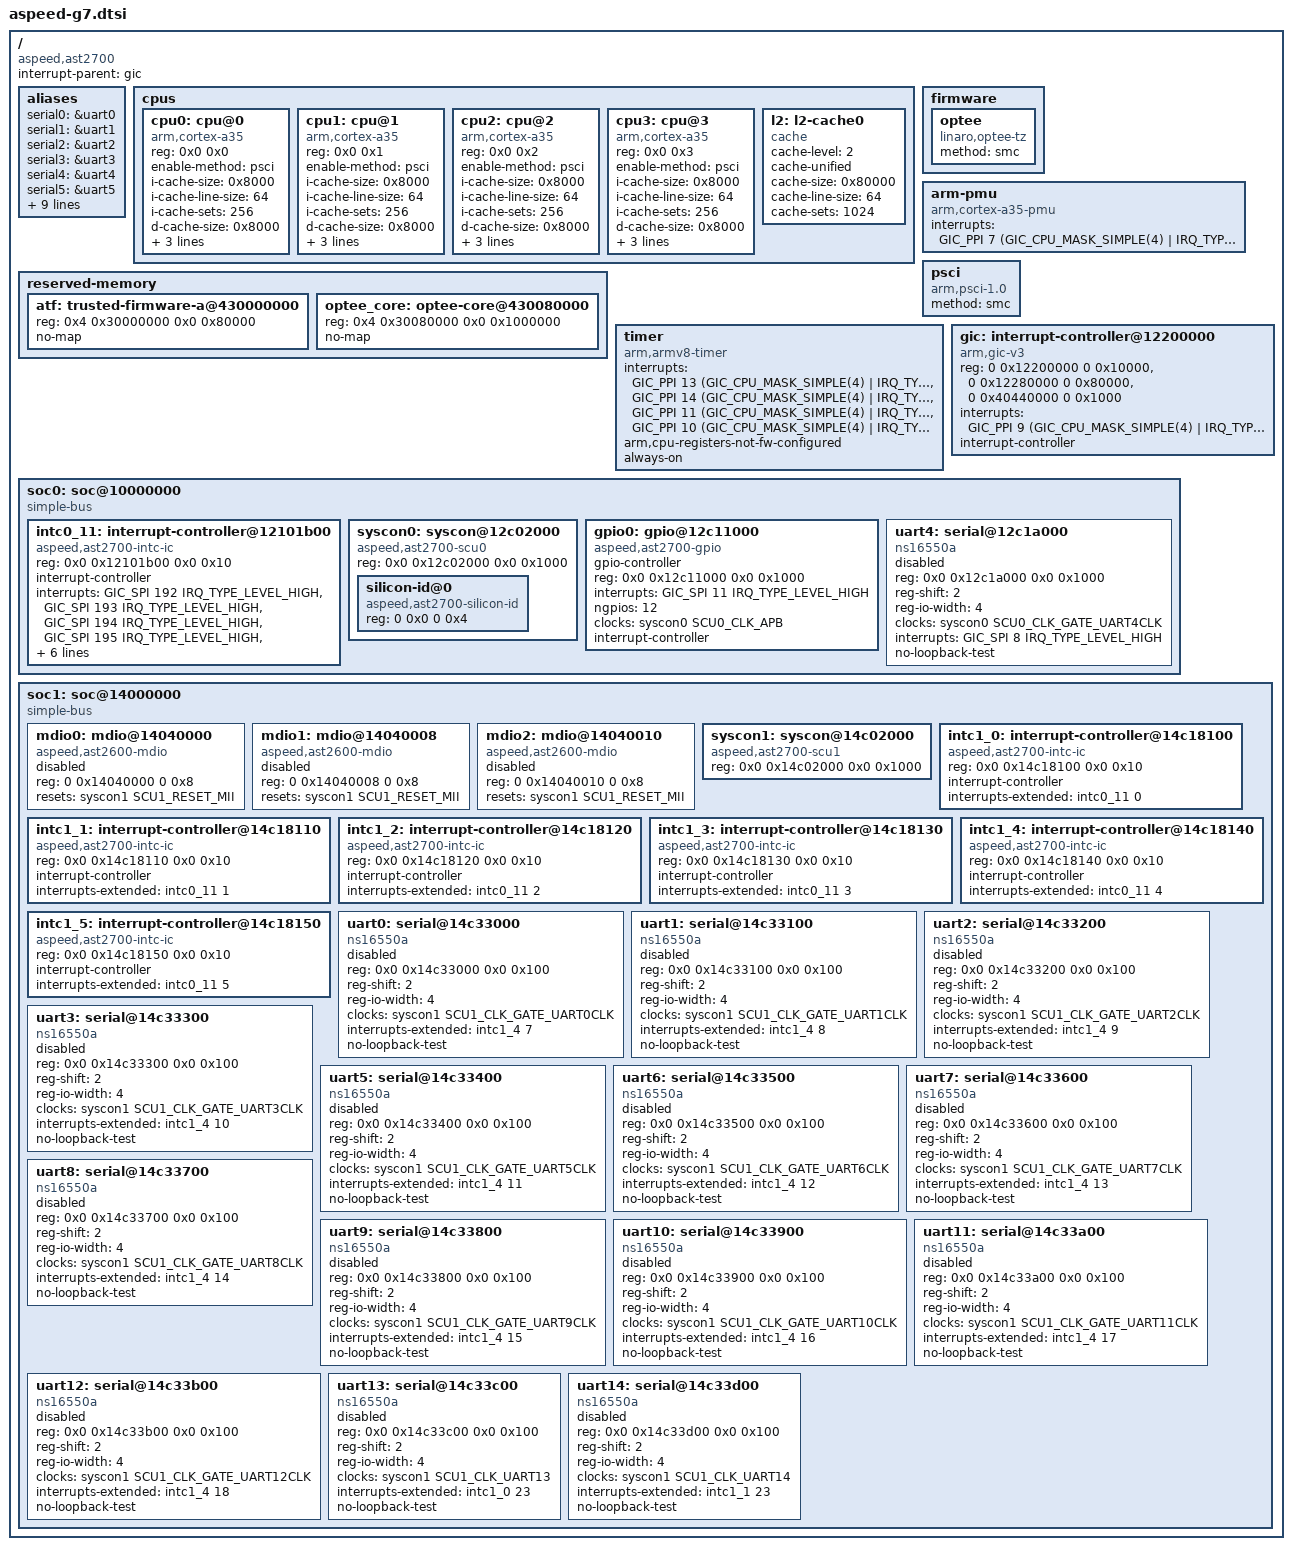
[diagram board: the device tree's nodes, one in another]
// SPDX-License-Identifier: GPL-2.0-or-later
#include <dt-bindings/clock/aspeed,ast2700-scu.h>
#include <dt-bindings/reset/aspeed,ast2700-scu.h>
#include <dt-bindings/interrupt-controller/arm-gic.h>

/ {
	compatible = "aspeed,ast2700";
	#address-cells = <2>;
	#size-cells = <2>;
	interrupt-parent = <&gic>;

	aliases {
		serial0 = &uart0;
		serial1 = &uart1;
		serial2 = &uart2;
		serial3 = &uart3;
		serial4 = &uart4;
		serial5 = &uart5;
		serial6 = &uart6;
		serial7 = &uart7;
		serial8 = &uart8;
		serial9 = &uart9;
		serial10 = &uart10;
		serial11 = &uart11;
		serial12 = &uart12;
		serial13 = &uart13;
		serial14 = &uart14;
	};

	cpus {
		#address-cells = <2>;
		#size-cells = <0>;

		cpu0: cpu@0 {
			device_type = "cpu";
			compatible = "arm,cortex-a35";
			reg = <0x0 0x0>;
			enable-method = "psci";
			i-cache-size = <0x8000>;
			i-cache-line-size = <64>;
			i-cache-sets = <256>;
			d-cache-size = <0x8000>;
			d-cache-line-size = <64>;
			d-cache-sets = <128>;
			next-level-cache = <&l2>;
		};

		cpu1: cpu@1 {
			device_type = "cpu";
			compatible = "arm,cortex-a35";
			reg = <0x0 0x1>;
			enable-method = "psci";
			i-cache-size = <0x8000>;
			i-cache-line-size = <64>;
			i-cache-sets = <256>;
			d-cache-size = <0x8000>;
			d-cache-line-size = <64>;
			d-cache-sets = <128>;
			next-level-cache = <&l2>;
		};

		cpu2: cpu@2 {
			device_type = "cpu";
			compatible = "arm,cortex-a35";
			reg = <0x0 0x2>;
			enable-method = "psci";
			i-cache-size = <0x8000>;
			i-cache-line-size = <64>;
			i-cache-sets = <256>;
			d-cache-size = <0x8000>;
			d-cache-line-size = <64>;
			d-cache-sets = <128>;
			next-level-cache = <&l2>;
		};

		cpu3: cpu@3 {
			device_type = "cpu";
			compatible = "arm,cortex-a35";
			reg = <0x0 0x3>;
			enable-method = "psci";
			i-cache-size = <0x8000>;
			i-cache-line-size = <64>;
			i-cache-sets = <256>;
			d-cache-size = <0x8000>;
			d-cache-line-size = <64>;
			d-cache-sets = <128>;
			next-level-cache = <&l2>;
		};

		l2: l2-cache0 {
			compatible = "cache";
			cache-level = <2>;
			cache-unified;
			cache-size = <0x80000>;
			cache-line-size = <64>;
			cache-sets = <1024>;
		};
	};

	firmware {
		optee: optee {
			compatible = "linaro,optee-tz";
			method = "smc";
		};
	};

	reserved-memory {
		#address-cells = <2>;
		#size-cells = <2>;
		ranges;

		atf: trusted-firmware-a@430000000 {
			reg = <0x4 0x30000000 0x0 0x80000>;
			no-map;
		};

		optee_core: optee-core@430080000 {
			reg = <0x4 0x30080000 0x0 0x1000000>;
			no-map;
		};
	};

	arm-pmu {
		compatible = "arm,cortex-a35-pmu";
		interrupts = <GIC_PPI 7 (GIC_CPU_MASK_SIMPLE(4) | IRQ_TYPE_LEVEL_HIGH)>;
	};

	psci {
		compatible = "arm,psci-1.0";
		method = "smc";
	};

	timer {
		compatible = "arm,armv8-timer";
		interrupts = <GIC_PPI 13 (GIC_CPU_MASK_SIMPLE(4) | IRQ_TYPE_LEVEL_LOW)>,
			     <GIC_PPI 14 (GIC_CPU_MASK_SIMPLE(4) | IRQ_TYPE_LEVEL_LOW)>,
			     <GIC_PPI 11 (GIC_CPU_MASK_SIMPLE(4) | IRQ_TYPE_LEVEL_LOW)>,
			     <GIC_PPI 10 (GIC_CPU_MASK_SIMPLE(4) | IRQ_TYPE_LEVEL_LOW)>;
		arm,cpu-registers-not-fw-configured;
		always-on;
	};

	gic: interrupt-controller@12200000 {
		compatible = "arm,gic-v3";
		reg = <0 0x12200000 0 0x10000>, /* GICD */
		      <0 0x12280000 0 0x80000>, /* GICR */
		      <0 0x40440000 0 0x1000>;  /* GICC */
		interrupts = <GIC_PPI 9 (GIC_CPU_MASK_SIMPLE(4) | IRQ_TYPE_LEVEL_HIGH)>;
		#interrupt-cells = <3>;
		interrupt-controller;
	};

	soc0: soc@10000000 {
		compatible = "simple-bus";
		#address-cells = <2>;
		#size-cells = <2>;
		ranges;

		intc0_11: interrupt-controller@12101b00 {
			compatible = "aspeed,ast2700-intc-ic";
			reg = <0x0 0x12101b00 0x0 0x10>;
			#interrupt-cells = <1>;
			interrupt-controller;
			interrupts = <GIC_SPI 192 IRQ_TYPE_LEVEL_HIGH>,
					<GIC_SPI 193 IRQ_TYPE_LEVEL_HIGH>,
					<GIC_SPI 194 IRQ_TYPE_LEVEL_HIGH>,
					<GIC_SPI 195 IRQ_TYPE_LEVEL_HIGH>,
					<GIC_SPI 196 IRQ_TYPE_LEVEL_HIGH>,
					<GIC_SPI 197 IRQ_TYPE_LEVEL_HIGH>,
					<GIC_SPI 198 IRQ_TYPE_LEVEL_HIGH>,
					<GIC_SPI 199 IRQ_TYPE_LEVEL_HIGH>,
					<GIC_SPI 200 IRQ_TYPE_LEVEL_HIGH>,
					<GIC_SPI 201 IRQ_TYPE_LEVEL_HIGH>;
		};

		syscon0: syscon@12c02000 {
			compatible = "aspeed,ast2700-scu0", "syscon", "simple-mfd";
			reg = <0x0 0x12c02000 0x0 0x1000>;
			ranges = <0x0 0x0 0 0x12c02000 0 0x1000>;
			#address-cells = <2>;
			#size-cells = <2>;
			#clock-cells = <1>;
			#reset-cells = <1>;

			silicon-id@0 {
				compatible = "aspeed,ast2700-silicon-id", "aspeed,silicon-id";
				reg = <0 0x0 0 0x4>;
			};

		};

		gpio0: gpio@12c11000 {
			#gpio-cells = <2>;
			gpio-controller;
			compatible = "aspeed,ast2700-gpio";
			reg = <0x0 0x12c11000 0x0 0x1000>;
			interrupts = <GIC_SPI 11 IRQ_TYPE_LEVEL_HIGH>;
			ngpios = <12>;
			clocks = <&syscon0 SCU0_CLK_APB>;
			interrupt-controller;
			#interrupt-cells = <2>;
		};

		uart4: serial@12c1a000 {
			compatible = "ns16550a";
			reg = <0x0 0x12c1a000 0x0 0x1000>;
			reg-shift = <2>;
			reg-io-width = <4>;
			clocks = <&syscon0 SCU0_CLK_GATE_UART4CLK>;
			interrupts = <GIC_SPI 8 IRQ_TYPE_LEVEL_HIGH>;
			no-loopback-test;
			status = "disabled";
		};
	};

	soc1: soc@14000000 {
		compatible = "simple-bus";
		#address-cells = <2>;
		#size-cells = <2>;
		ranges;

		mdio0: mdio@14040000 {
			compatible = "aspeed,ast2600-mdio";
			reg = <0 0x14040000 0 0x8>;
			resets = <&syscon1 SCU1_RESET_MII>;
			status = "disabled";
		};

		mdio1: mdio@14040008 {
			compatible = "aspeed,ast2600-mdio";
			reg = <0 0x14040008 0 0x8>;
			resets = <&syscon1 SCU1_RESET_MII>;
			status = "disabled";
		};

		mdio2: mdio@14040010 {
			compatible = "aspeed,ast2600-mdio";
			reg = <0 0x14040010 0 0x8>;
			resets = <&syscon1 SCU1_RESET_MII>;
			status = "disabled";
		};

		syscon1: syscon@14c02000 {
			compatible = "aspeed,ast2700-scu1";
			reg = <0x0 0x14c02000 0x0 0x1000>;
			#clock-cells = <1>;
			#reset-cells = <1>;
		};

		intc1_0: interrupt-controller@14c18100 {
			compatible = "aspeed,ast2700-intc-ic";
			reg = <0x0 0x14c18100 0x0 0x10>;
			#interrupt-cells = <1>;
			interrupt-controller;
			interrupts-extended = <&intc0_11 0>;
		};

		intc1_1: interrupt-controller@14c18110 {
			compatible = "aspeed,ast2700-intc-ic";
			reg = <0x0 0x14c18110 0x0 0x10>;
			#interrupt-cells = <1>;
			interrupt-controller;
			interrupts-extended = <&intc0_11 1>;
		};

		intc1_2: interrupt-controller@14c18120 {
			compatible = "aspeed,ast2700-intc-ic";
			reg = <0x0 0x14c18120 0x0 0x10>;
			#interrupt-cells = <1>;
			interrupt-controller;
			interrupts-extended = <&intc0_11 2>;
		};

		intc1_3: interrupt-controller@14c18130 {
			compatible = "aspeed,ast2700-intc-ic";
			reg = <0x0 0x14c18130 0x0 0x10>;
			#interrupt-cells = <1>;
			interrupt-controller;
			interrupts-extended = <&intc0_11 3>;
		};

		intc1_4: interrupt-controller@14c18140 {
			compatible = "aspeed,ast2700-intc-ic";
			reg = <0x0 0x14c18140 0x0 0x10>;
			#interrupt-cells = <1>;
			interrupt-controller;
			interrupts-extended = <&intc0_11 4>;
		};

		intc1_5: interrupt-controller@14c18150 {
			compatible = "aspeed,ast2700-intc-ic";
			reg = <0x0 0x14c18150 0x0 0x10>;
			#interrupt-cells = <1>;
			interrupt-controller;
			interrupts-extended = <&intc0_11 5>;
		};

		uart0: serial@14c33000 {
			compatible = "ns16550a";
			reg = <0x0 0x14c33000 0x0 0x100>;
			reg-shift = <2>;
			reg-io-width = <4>;
			clocks = <&syscon1 SCU1_CLK_GATE_UART0CLK>;
			interrupts-extended = <&intc1_4 7>;
			no-loopback-test;
			status = "disabled";
		};

		uart1: serial@14c33100 {
			compatible = "ns16550a";
			reg = <0x0 0x14c33100 0x0 0x100>;
			reg-shift = <2>;
			reg-io-width = <4>;
			clocks = <&syscon1 SCU1_CLK_GATE_UART1CLK>;
			interrupts-extended = <&intc1_4 8>;
			no-loopback-test;
			status = "disabled";
		};

		uart2: serial@14c33200 {
			compatible = "ns16550a";
			reg = <0x0 0x14c33200 0x0 0x100>;
			reg-shift = <2>;
			reg-io-width = <4>;
			clocks = <&syscon1 SCU1_CLK_GATE_UART2CLK>;
			interrupts-extended = <&intc1_4 9>;
			no-loopback-test;
			status = "disabled";
		};

		uart3: serial@14c33300 {
			compatible = "ns16550a";
			reg = <0x0 0x14c33300 0x0 0x100>;
			reg-shift = <2>;
			reg-io-width = <4>;
			clocks = <&syscon1 SCU1_CLK_GATE_UART3CLK>;
			interrupts-extended = <&intc1_4 10>;
			no-loopback-test;
			status = "disabled";
		};

		uart5: serial@14c33400 {
			compatible = "ns16550a";
			reg = <0x0 0x14c33400 0x0 0x100>;
			reg-shift = <2>;
			reg-io-width = <4>;
			clocks = <&syscon1 SCU1_CLK_GATE_UART5CLK>;
			interrupts-extended = <&intc1_4 11>;
			no-loopback-test;
			status = "disabled";
		};

		uart6: serial@14c33500 {
			compatible = "ns16550a";
			reg = <0x0 0x14c33500 0x0 0x100>;
			reg-shift = <2>;
			reg-io-width = <4>;
			clocks = <&syscon1 SCU1_CLK_GATE_UART6CLK>;
			interrupts-extended = <&intc1_4 12>;
			no-loopback-test;
			status = "disabled";
		};

		uart7: serial@14c33600 {
			compatible = "ns16550a";
			reg = <0x0 0x14c33600 0x0 0x100>;
			reg-shift = <2>;
			reg-io-width = <4>;
			clocks = <&syscon1 SCU1_CLK_GATE_UART7CLK>;
			interrupts-extended = <&intc1_4 13>;
			no-loopback-test;
			status = "disabled";
		};

		uart8: serial@14c33700 {
			compatible = "ns16550a";
			reg = <0x0 0x14c33700 0x0 0x100>;
			reg-shift = <2>;
			reg-io-width = <4>;
			clocks = <&syscon1 SCU1_CLK_GATE_UART8CLK>;
			interrupts-extended = <&intc1_4 14>;
			no-loopback-test;
			status = "disabled";
		};

		uart9: serial@14c33800 {
			compatible = "ns16550a";
			reg = <0x0 0x14c33800 0x0 0x100>;
			reg-shift = <2>;
			reg-io-width = <4>;
			clocks = <&syscon1 SCU1_CLK_GATE_UART9CLK>;
			interrupts-extended = <&intc1_4 15>;
			no-loopback-test;
			status = "disabled";
		};

		uart10: serial@14c33900 {
			compatible = "ns16550a";
			reg = <0x0 0x14c33900 0x0 0x100>;
			reg-shift = <2>;
			reg-io-width = <4>;
			clocks = <&syscon1 SCU1_CLK_GATE_UART10CLK>;
			interrupts-extended = <&intc1_4 16>;
			no-loopback-test;
			status = "disabled";
		};

		uart11: serial@14c33a00 {
			compatible = "ns16550a";
			reg = <0x0 0x14c33a00 0x0 0x100>;
			reg-shift = <2>;
			reg-io-width = <4>;
			clocks = <&syscon1 SCU1_CLK_GATE_UART11CLK>;
			interrupts-extended = <&intc1_4 17>;
			no-loopback-test;
			status = "disabled";
		};

		uart12: serial@14c33b00 {
			compatible = "ns16550a";
			reg = <0x0 0x14c33b00 0x0 0x100>;
			reg-shift = <2>;
			reg-io-width = <4>;
			clocks = <&syscon1 SCU1_CLK_GATE_UART12CLK>;
			interrupts-extended = <&intc1_4 18>;
			no-loopback-test;
			status = "disabled";
		};

		uart13: serial@14c33c00 {
			compatible = "ns16550a";
			reg = <0x0 0x14c33c00 0x0 0x100>;
			reg-shift = <2>;
			reg-io-width = <4>;
			clocks = <&syscon1 SCU1_CLK_UART13>;
			interrupts-extended = <&intc1_0 23>;
			no-loopback-test;
			status = "disabled";
		};

		uart14: serial@14c33d00 {
			compatible = "ns16550a";
			reg = <0x0 0x14c33d00 0x0 0x100>;
			reg-shift = <2>;
			reg-io-width = <4>;
			clocks = <&syscon1 SCU1_CLK_UART14>;
			interrupts-extended = <&intc1_1 23>;
			no-loopback-test;
			status = "disabled";
		};
	};
};
